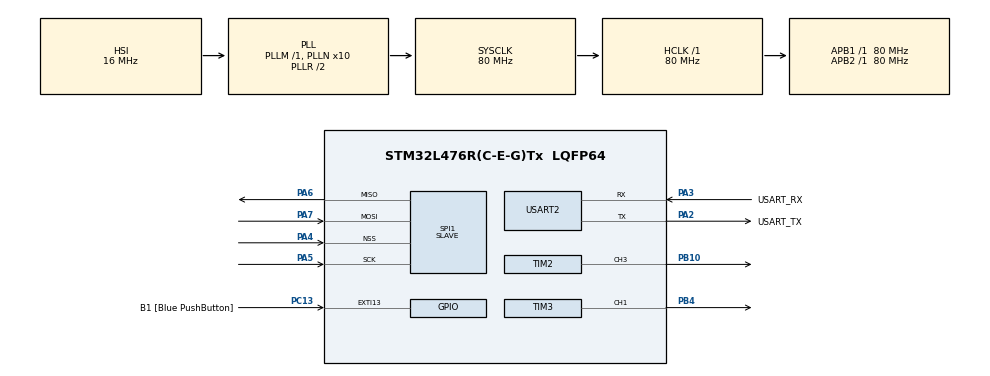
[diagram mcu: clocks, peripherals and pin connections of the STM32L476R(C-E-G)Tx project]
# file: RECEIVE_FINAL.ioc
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Dma.Request0=SPI1_RX
Dma.SPI1_RX.0.Direction=DMA_PERIPH_TO_MEMORY
Dma.SPI1_RX.0.Instance=DMA1_Channel2
Dma.SPI1_RX.0.MemDataAlignment=DMA_MDATAALIGN_BYTE
Dma.SPI1_RX.0.MemInc=DMA_MINC_ENABLE
Dma.SPI1_RX.0.Mode=DMA_NORMAL
Dma.SPI1_RX.0.PeriphDataAlignment=DMA_PDATAALIGN_BYTE
Dma.SPI1_RX.0.PeriphInc=DMA_PINC_DISABLE
Dma.SPI1_RX.0.Priority=DMA_PRIORITY_LOW
FREERTOS.Tasks01=defaultTask,0,128,StartDefaultTask,Default,NULL,Dynamic,NULL,NULL
Mcu.Family=STM32L4
Mcu.Name=STM32L476R(C-E-G)Tx
Mcu.Package=LQFP64
NVIC.DMA1_Channel2_IRQn=true\:5\:0\:false\:false\:true\:true\:false\:true\:true
NVIC.PriorityGroup=NVIC_PRIORITYGROUP_4
PA13\ (JTMS-SWDIO).GPIO_Label=TMS
PA13\ (JTMS-SWDIO).Signal=SYS_JTMS-SWDIO
PA14\ (JTCK-SWCLK).GPIO_Label=TCK
PA14\ (JTCK-SWCLK).Signal=SYS_JTCK-SWCLK
PA2.GPIO_Label=USART_TX
PA2.GPIO_Mode=GPIO_MODE_AF_PP
PA2.GPIO_PuPd=GPIO_NOPULL
PA2.GPIO_Speed=GPIO_SPEED_FREQ_VERY_HIGH
PA2.Mode=Asynchronous
PA2.Signal=USART2_TX
PA3.GPIO_Label=USART_RX
PA3.GPIO_Mode=GPIO_MODE_AF_PP
PA3.GPIO_PuPd=GPIO_NOPULL
PA3.GPIO_Speed=GPIO_SPEED_FREQ_VERY_HIGH
PA3.Mode=Asynchronous
PA3.Signal=USART2_RX
PA4.Mode=NSS_Signal_Hard_Input
PA4.Signal=SPI1_NSS
PA5.Mode=Full_Duplex_Slave
PA5.Signal=SPI1_SCK
PA6.Mode=Full_Duplex_Slave
PA6.Signal=SPI1_MISO
PA7.Mode=Full_Duplex_Slave
PA7.Signal=SPI1_MOSI
PB10.Signal=S_TIM2_CH3
PB3\ (JTDO-TRACESWO).GPIO_Label=SWO
PB3\ (JTDO-TRACESWO).Signal=SYS_JTDO-SWO
PB4\ (NJTRST).Signal=S_TIM3_CH1
PC13.GPIO_Label=B1 [Blue PushButton]
PC13.GPIO_ModeDefaultEXTI=GPIO_MODE_IT_FALLING
PC13.GPIO_PuPd=GPIO_NOPULL
PC13.Signal=GPXTI13
PC14-OSC32_IN\ (PC14).Signal=RCC_OSC32_IN
PC15-OSC32_OUT\ (PC15).Signal=RCC_OSC32_OUT
PH0-OSC_IN\ (PH0).Signal=RCC_OSC_IN
PH1-OSC_OUT\ (PH1).Signal=RCC_OSC_OUT
ProjectManager.HeapSize=0x200
ProjectManager.StackSize=0x400
ProjectManager.TargetToolchain=STM32CubeIDE
RCC.ADCFreq_Value=64000000
RCC.AHBFreq_Value=80000000
RCC.APB1Freq_Value=80000000
RCC.APB1TimFreq_Value=80000000
RCC.APB2Freq_Value=80000000
RCC.APB2TimFreq_Value=80000000
RCC.CortexFreq_Value=80000000
RCC.HCLKFreq_Value=80000000
RCC.HSE_VALUE=8000000
RCC.HSI_VALUE=16000000
RCC.LSE_VALUE=32768
RCC.MSI_VALUE=4000000
RCC.PLLN=10
RCC.PLLSourceVirtual=RCC_PLLSOURCE_HSI
RCC.PREFETCH_ENABLE=1
RCC.SYSCLKFreq_VALUE=80000000
RCC.SYSCLKSource=RCC_SYSCLKSOURCE_PLLCLK
RCC.USBFreq_Value=64000000
RCC.VCOOutputFreq_Value=160000000
SH.S_TIM2_CH3.0=TIM2_CH3,PWM Generation3 CH3
SH.S_TIM3_CH1.0=TIM3_CH1,PWM Generation1 CH1
SPI1.DataSize=SPI_DATASIZE_8BIT
SPI1.Direction=SPI_DIRECTION_2LINES
SPI1.Mode=SPI_MODE_SLAVE
SPI1.VirtualNSS=VM_NSSHARD
SPI1.VirtualType=VM_SLAVE
TIM2.Channel-PWM\ Generation3\ CH3=TIM_CHANNEL_3
TIM2.Period=19999
TIM2.Prescaler=79
TIM3.Channel-PWM\ Generation1\ CH1=TIM_CHANNEL_1
TIM3.Period=19999
TIM3.Prescaler=79
USART2.VirtualMode-Asynchronous=VM_ASYNC
VP_FREERTOS_VS_CMSIS_V1.Mode=CMSIS_V1
board=NUCLEO-L476RG

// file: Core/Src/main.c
/* USER CODE BEGIN Header */
/**
  ******************************************************************************
  * @file           : main.c
  * @brief          : Main program body (peripherals + ISRs + RTOS start)
  ******************************************************************************
  * @attention
  * Copyright (c) 2025 STMicroelectronics.
  * All rights reserved.
  * This software is licensed under terms in the LICENSE file in the root dir.
  ******************************************************************************
  */
/* USER CODE END Header */
#include "main.h"
#include "cmsis_os.h"

/* USER CODE BEGIN Includes */
#include <string.h>
#include <stdio.h>
#include "FreeRTOS.h"
#include "queue.h"
/* USER CODE END Includes */

/* USER CODE BEGIN PTD */
typedef struct { uint8_t bytes[64]; } SpiFrame_t;
/* USER CODE END PTD */

/* USER CODE BEGIN PD */
#define NSS_MON_PORT GPIOB
#define NSS_MON_PIN  GPIO_PIN_0
#define FRAME_LEN    64
/* USER CODE END PD */

SPI_HandleTypeDef hspi1;
DMA_HandleTypeDef hdma_spi1_rx;
DMA_HandleTypeDef hdma_spi1_tx;   /* présent si CubeMX le référence dans MSP */
TIM_HandleTypeDef htim2;          /* TIM2_CH3 -> PB10 (AF1) : direction */
TIM_HandleTypeDef htim3;          /* TIM3_CH1 -> PB4  (AF2) : vitesse */
UART_HandleTypeDef huart2;

/* USER CODE BEGIN PV */
static uint8_t spi_rx_buf[FRAME_LEN];
extern QueueHandle_t spiRxQueue;  /* vient de freertos.c */
/* USER CODE END PV */

void SystemClock_Config(void);
static void MX_GPIO_Init(void);
static void MX_DMA_Init(void);
static void MX_SPI1_Init(void);
static void MX_USART2_UART_Init(void);
static void MX_TIM2_Init(void);
static void MX_TIM3_Init(void);
void MX_FREERTOS_Init(void);

int main(void)
{
  HAL_Init();
  SystemClock_Config();

  MX_GPIO_Init();
  MX_DMA_Init();
  MX_SPI1_Init();
  MX_USART2_UART_Init();
  MX_TIM2_Init();     /* Direction */
  MX_TIM3_Init();     /* Vitesse  */

  MX_FREERTOS_Init();
  osKernelStart();

  while (1) { }
}

/* === Clocks ================================================================ */
void SystemClock_Config(void)
{
  RCC_OscInitTypeDef RCC_OscInitStruct = {0};
  RCC_ClkInitTypeDef RCC_ClkInitStruct = {0};

  if (HAL_PWREx_ControlVoltageScaling(PWR_REGULATOR_VOLTAGE_SCALE1) != HAL_OK) {
    Error_Handler();
  }

  RCC_OscInitStruct.OscillatorType      = RCC_OSCILLATORTYPE_HSI;
  RCC_OscInitStruct.HSIState            = RCC_HSI_ON;
  RCC_OscInitStruct.HSICalibrationValue = RCC_HSICALIBRATION_DEFAULT;
  RCC_OscInitStruct.PLL.PLLState        = RCC_PLL_ON;
  RCC_OscInitStruct.PLL.PLLSource       = RCC_PLLSOURCE_HSI;
  RCC_OscInitStruct.PLL.PLLM            = 1;
  RCC_OscInitStruct.PLL.PLLN            = 10;
  RCC_OscInitStruct.PLL.PLLP            = RCC_PLLP_DIV7;
  RCC_OscInitStruct.PLL.PLLQ            = RCC_PLLQ_DIV2;
  RCC_OscInitStruct.PLL.PLLR            = RCC_PLLR_DIV2;
  if (HAL_RCC_OscConfig(&RCC_OscInitStruct) != HAL_OK) Error_Handler();

  RCC_ClkInitStruct.ClockType      = RCC_CLOCKTYPE_HCLK|RCC_CLOCKTYPE_SYSCLK
                                   | RCC_CLOCKTYPE_PCLK1|RCC_CLOCKTYPE_PCLK2;
  RCC_ClkInitStruct.SYSCLKSource   = RCC_SYSCLKSOURCE_PLLCLK;
  RCC_ClkInitStruct.AHBCLKDivider  = RCC_SYSCLK_DIV1;
  RCC_ClkInitStruct.APB1CLKDivider = RCC_HCLK_DIV1;
  RCC_ClkInitStruct.APB2CLKDivider = RCC_HCLK_DIV1;
  if (HAL_RCC_ClockConfig(&RCC_ClkInitStruct, FLASH_LATENCY_4) != HAL_OK) Error_Handler();
}

/* === SPI1 (slave) ========================================================== */
static void MX_SPI1_Init(void)
{
  hspi1.Instance               = SPI1;
  hspi1.Init.Mode              = SPI_MODE_SLAVE;
  hspi1.Init.Direction         = SPI_DIRECTION_2LINES;
  hspi1.Init.DataSize          = SPI_DATASIZE_8BIT;
  hspi1.Init.CLKPolarity       = SPI_POLARITY_LOW;
  hspi1.Init.CLKPhase          = SPI_PHASE_1EDGE;
  hspi1.Init.NSS               = SPI_NSS_HARD_INPUT;
  hspi1.Init.FirstBit          = SPI_FIRSTBIT_MSB;
  hspi1.Init.TIMode            = SPI_TIMODE_DISABLE;
  hspi1.Init.CRCCalculation    = SPI_CRCCALCULATION_DISABLE;
  hspi1.Init.CRCPolynomial     = 7;
  hspi1.Init.CRCLength         = SPI_CRC_LENGTH_DATASIZE;
  hspi1.Init.NSSPMode          = SPI_NSS_PULSE_DISABLE;
  if (HAL_SPI_Init(&hspi1) != HAL_OK) Error_Handler();
}

/* === UART2 ================================================================ */
static void MX_USART2_UART_Init(void)
{
  huart2.Instance                    = USART2;
  huart2.Init.BaudRate               = 115200;
  huart2.Init.WordLength             = UART_WORDLENGTH_8B;
  huart2.Init.StopBits               = UART_STOPBITS_1;
  huart2.Init.Parity                 = UART_PARITY_NONE;
  huart2.Init.Mode                   = UART_MODE_TX_RX;
  huart2.Init.HwFlowCtl              = UART_HWCONTROL_NONE;
  huart2.Init.OverSampling           = UART_OVERSAMPLING_16;
  huart2.Init.OneBitSampling         = UART_ONE_BIT_SAMPLE_DISABLE;
  huart2.AdvancedInit.AdvFeatureInit = UART_ADVFEATURE_NO_INIT;
  if (HAL_UART_Init(&huart2) != HAL_OK) Error_Handler();
}

/* === DMA (SPI1 RX sur DMA1_Ch2) =========================================== */
static void MX_DMA_Init(void)
{
  __HAL_RCC_DMA1_CLK_ENABLE();
  HAL_NVIC_SetPriority(DMA1_Channel2_IRQn, 5, 0);
  HAL_NVIC_EnableIRQ(DMA1_Channel2_IRQn);
}

/* === GPIO (PB0 EXTI pour NSS monitor) ===================================== */
static void MX_GPIO_Init(void)
{
  GPIO_InitTypeDef GPIO_InitStruct = {0};

  __HAL_RCC_GPIOC_CLK_ENABLE();
  __HAL_RCC_GPIOH_CLK_ENABLE();
  __HAL_RCC_GPIOA_CLK_ENABLE();
  __HAL_RCC_GPIOB_CLK_ENABLE();
  __HAL_RCC_SYSCFG_CLK_ENABLE();

  /* Bouton B1 (généré par Cube) */
  GPIO_InitStruct.Pin  = B1_Pin;
  GPIO_InitStruct.Mode = GPIO_MODE_IT_FALLING;
  GPIO_InitStruct.Pull = GPIO_NOPULL;
  HAL_GPIO_Init(B1_GPIO_Port, &GPIO_InitStruct);

  /* PB0 EXTI falling (copie NSS/CS de l’ESP32) */
  GPIO_InitStruct.Pin  = GPIO_PIN_0;
  GPIO_InitStruct.Mode = GPIO_MODE_IT_FALLING;
  GPIO_InitStruct.Pull = GPIO_PULLUP;
  HAL_GPIO_Init(GPIOB, &GPIO_InitStruct);

  HAL_NVIC_SetPriority(EXTI0_IRQn, 5, 0);
  HAL_NVIC_EnableIRQ(EXTI0_IRQn);
}

/* === TIM2_CH3 (PB10) & TIM3_CH1 (PB4) en 50 Hz ============================ */
static void MX_TIM2_Init(void)
{
  __HAL_RCC_TIM2_CLK_ENABLE();

  htim2.Instance = TIM2;
  htim2.Init.Prescaler         = 80 - 1;     /* 1 MHz */
  htim2.Init.CounterMode       = TIM_COUNTERMODE_UP;
  htim2.Init.Period            = 20000 - 1;  /* 20 ms (50 Hz) */
  htim2.Init.ClockDivision     = TIM_CLOCKDIVISION_DIV1;
  htim2.Init.AutoReloadPreload = TIM_AUTORELOAD_PRELOAD_DISABLE;
  if (HAL_TIM_PWM_Init(&htim2) != HAL_OK) Error_Handler();

  TIM_OC_InitTypeDef s = {0};
  s.OCMode     = TIM_OCMODE_PWM1;
  s.Pulse      = 1400;                       /* neutre */
  s.OCPolarity = TIM_OCPOLARITY_HIGH;
  s.OCFastMode = TIM_OCFAST_DISABLE;
  if (HAL_TIM_PWM_ConfigChannel(&htim2, &s, TIM_CHANNEL_3) != HAL_OK) Error_Handler();

  HAL_TIM_MspPostInit(&htim2);               /* configure PB10 AF1 */
}

static void MX_TIM3_Init(void)
{
  __HAL_RCC_TIM3_CLK_ENABLE();

  htim3.Instance = TIM3;
  htim3.Init.Prescaler         = 80 - 1;     /* 1 MHz */
  htim3.Init.CounterMode       = TIM_COUNTERMODE_UP;
  htim3.Init.Period            = 20000 - 1;  /* 20 ms (50 Hz) */
  htim3.Init.ClockDivision     = TIM_CLOCKDIVISION_DIV1;
  htim3.Init.AutoReloadPreload = TIM_AUTORELOAD_PRELOAD_DISABLE;
  if (HAL_TIM_PWM_Init(&htim3) != HAL_OK) Error_Handler();

  TIM_OC_InitTypeDef s = {0};
  s.OCMode     = TIM_OCMODE_PWM1;
  s.Pulse      = 1400;                       /* neutre */
  s.OCPolarity = TIM_OCPOLARITY_HIGH;
  s.OCFastMode = TIM_OCFAST_DISABLE;
  if (HAL_TIM_PWM_ConfigChannel(&htim3, &s, TIM_CHANNEL_1) != HAL_OK) Error_Handler();

  HAL_TIM_MspPostInit(&htim3);               /* configure PB4 AF2 */
}

/* === ISRs / Callbacks ====================================================== */
void HAL_GPIO_EXTI_Callback(uint16_t GPIO_Pin)
{
  if (GPIO_Pin == NSS_MON_PIN) {
    if (HAL_SPI_GetState(&hspi1) == HAL_SPI_STATE_READY) {
      (void)HAL_SPI_Receive_DMA(&hspi1, spi_rx_buf, FRAME_LEN);
    }
  }
}

void HAL_SPI_RxCpltCallback(SPI_HandleTypeDef *hspi)
{
  if (hspi->Instance == SPI1) {
    BaseType_t xHigherPriorityTaskWoken = pdFALSE;
    SpiFrame_t frame;
    memcpy(frame.bytes, spi_rx_buf, FRAME_LEN);
    if (spiRxQueue) {
      xQueueSendFromISR(spiRxQueue, &frame, &xHigherPriorityTaskWoken);
    }
    portYIELD_FROM_ISR(xHigherPriorityTaskWoken);
  }
}

void HAL_SPI_ErrorCallback(SPI_HandleTypeDef *hspi)
{
  if (hspi->Instance == SPI1) {
    (void)HAL_SPI_Abort(hspi);
  }
}

void Error_Handler(void)
{
  __disable_irq();
  while (1) { }
}

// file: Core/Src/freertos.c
/**
  ******************************************************************************
  * @file    freertos.c
  * @brief   RTOS objects: queues, tasks, MX_FREERTOS_Init()
  ******************************************************************************
  */

#include "cmsis_os.h"
#include "main.h"

/* FreeRTOS */
#include "FreeRTOS.h"
#include "queue.h"
#include "task.h"

/* C std */
#include <string.h>
#include <stdio.h>
#include <stdint.h>

/* Extern HAL handles (from main.c) */
extern UART_HandleTypeDef huart2;
extern TIM_HandleTypeDef  htim2;   /* TIM2_CH3 -> PB10 (AF1) */
extern TIM_HandleTypeDef  htim3;   /* TIM3_CH1 -> PB4  (AF2) */

/* Partagé avec l'ISR SPI */
QueueHandle_t spiRxQueue = NULL;

/* Etats (optionnel) */
volatile float LX_value;
volatile float RT_value;
volatile float LT_value;

/* Trame SPI brute */
#define FRAME_LEN  64
typedef struct { uint8_t bytes[FRAME_LEN]; } SpiFrame_t;

/* Protos */
static void StartDefaultTask(void const * argument);
void StartDirTask(void const * argument);
void StartSpdTask(void const * argument);

/* Format décodé (offset 3) */
typedef struct {
  uint32_t buttons;
  float    lx;
  float    ly;
  float    rx;
  float    ry;
  float    lt;
  float    rt;
} GamepadFrame_t;

static inline uint32_t read_u32_le(const uint8_t *p) { uint32_t v; memcpy(&v,p,4); return v; }
static inline float    read_f32_le(const uint8_t *p) { float    f; memcpy(&f,p,4); return f; }

static void decode_gamepad_frame(const uint8_t *data, GamepadFrame_t *out)
{
  size_t off = 3;  /* on saute 3 octets */
  out->buttons = read_u32_le(&data[off]); off += 4;
  out->lx      = read_f32_le(&data[off]); off += 4;
  out->ly      = read_f32_le(&data[off]); off += 4;
  out->rx      = read_f32_le(&data[off]); off += 4;
  out->ry      = read_f32_le(&data[off]); off += 4;
  out->lt      = read_f32_le(&data[off]); off += 4;
  out->rt      = read_f32_le(&data[off]); off += 4;
}

/* Messages des queues */
typedef struct { float lx; } DirectionMsg;
typedef struct { float lt; float rt; } VitesseMsg;

QueueHandle_t qDirection = NULL;
QueueHandle_t qVitesse   = NULL;

/* Bornes et gains */
static const uint16_t DIR_MIN    = 1200;
static const uint16_t DIR_CENTER = 1400;
static const uint16_t DIR_MAX    = 1600;
static const int16_t  DIR_SCALE  = 200;   /* duty_dir = 1400 - 200*lx */

static const uint16_t SPD_CENTER = 1400;  /* test_v1 neutre */
static const uint16_t SPD_MIN    = 1300;
static const uint16_t SPD_MAX    = 1500;
static const int16_t  SPD_SCALE  = 50;    /* duty_spd = 1400 + 50*(rt - lt) */

static inline int clamp_i(int v, int lo, int hi) {
  if (v < lo) return lo; if (v > hi) return hi; return v;
}

static void fmt_f2(char *dst, size_t sz, float v)
{
  int neg = (v < 0.0f);
  float a = neg ? -v : v;
  int32_t ip = (int32_t)a;
  int32_t frac = (int32_t)((a - (float)ip)*100.0f + 0.5f);
  if (frac >= 100) { frac -= 100; ip += 1; }
  snprintf(dst, sz, neg ? "-%ld.%02ld" : "%ld.%02ld", (long)ip, (long)frac);
}

/* Log de config PWM et AF des pins */
static void LogPwmSetupOnce(void)
{
  uint32_t t2_psc = htim2.Init.Prescaler, t2_arr = htim2.Init.Period;
  uint32_t t3_psc = htim3.Init.Prescaler, t3_arr = htim3.Init.Period;
  uint32_t af_pb10 = (GPIOB->AFR[1] >> ((10U-8U)*4U)) & 0xF;  /* PB10 -> AFRH idx 2 */
  uint32_t af_pb4  = (GPIOB->AFR[0] >> (4U*4U)) & 0xF;        /* PB4  -> AFRL idx 4  */

  char buf[196];
  int n = snprintf(buf, sizeof buf,
      "[CFG] TIM2:PSC=%lu ARR=%lu  TIM3:PSC=%lu ARR=%lu\r\n"
      "[CFG] PB10.AF=%lu (exp 1)   PB4.AF=%lu (exp 2)\r\n"
      "[CFG] DIR[%u,%u,%u]  SPD[%u,%u,%u]\r\n",
      (unsigned long)t2_psc, (unsigned long)t2_arr,
      (unsigned long)t3_psc, (unsigned long)t3_arr,
      (unsigned long)af_pb10, (unsigned long)af_pb4,
      DIR_MIN, DIR_CENTER, DIR_MAX, SPD_MIN, SPD_CENTER, SPD_MAX);
  HAL_UART_Transmit(&huart2, (uint8_t*)buf, (uint16_t)n, 100);
}

/* Init FreeRTOS */
void MX_FREERTOS_Init(void)
{
  /* Banniere pour être sûr de l’image flashée */
  {
    char b[96];
    int n = snprintf(b, sizeof b, "[BOOT] FW=%s %s\r\n", __DATE__, __TIME__);
    HAL_UART_Transmit(&huart2, (uint8_t*)b, (uint16_t)n, 50);
  }

  spiRxQueue = xQueueCreate(8, sizeof(SpiFrame_t));
  if (!spiRxQueue) { taskDISABLE_INTERRUPTS(); for(;;){} }

  qDirection = xQueueCreate(1, sizeof(DirectionMsg));
  qVitesse   = xQueueCreate(1, sizeof(VitesseMsg));

  {
    char buf[96];
    int n = snprintf(buf, sizeof buf, "[BOOT] qDir=%p qSpd=%p free=%lu min=%lu\r\n",
                     (void*)qDirection, (void*)qVitesse,
                     (unsigned long)xPortGetFreeHeapSize(),
                     (unsigned long)xPortGetMinimumEverFreeHeapSize());
    HAL_UART_Transmit(&huart2, (uint8_t*)buf, (uint16_t)n, 50);
  }

  osThreadDef(defaultTask, StartDefaultTask, osPriorityNormal, 0, 256);
  osThreadId defH = osThreadCreate(osThread(defaultTask), NULL);

  osThreadDef(dirTask, StartDirTask, osPriorityAboveNormal, 0, 256);
  osThreadId dirH = osThreadCreate(osThread(dirTask), NULL);

  osThreadDef(spdTask, StartSpdTask, osPriorityAboveNormal, 0, 256);
  osThreadId spdH = osThreadCreate(osThread(spdTask), NULL);

  {
    char buf[96];
    int n = snprintf(buf, sizeof buf, "[BOOT] default=%p dir=%p spd=%p\r\n",
                     defH, dirH, spdH);
    HAL_UART_Transmit(&huart2, (uint8_t*)buf, (uint16_t)n, 50);
  }

  LogPwmSetupOnce();
}

/* ==== TASKS ================================================================ */
static void StartDefaultTask(void const * argument)
{
  SpiFrame_t frame;
  GamepadFrame_t g;

  for(;;) {
    if (xQueueReceive(spiRxQueue, &frame, portMAX_DELAY) == pdTRUE) {
      decode_gamepad_frame(frame.bytes, &g);

      LT_value = g.lt;
      RT_value = g.rt;
      LX_value = g.lx;

      DirectionMsg dmsg = { .lx = LX_value };
      VitesseMsg   vmsg = { .lt = LT_value, .rt = RT_value };
      (void)xQueueOverwrite(qDirection, &dmsg);
      (void)xQueueOverwrite(qVitesse,   &vmsg);

      char lx[12], lt[12], rt[12], line[64];
      fmt_f2(lx, sizeof lx, LX_value);
      fmt_f2(lt, sizeof lt, LT_value);
      fmt_f2(rt, sizeof rt, RT_value);
      int n = snprintf(line, sizeof line, "LX=%s  LT=%s  RT=%s\r\n", lx, lt, rt);
      HAL_UART_Transmit(&huart2, (uint8_t*)line, (uint16_t)n, 50);
    }
  }
}

/* Direction : TIM2_CH3 / PB10 */
void StartDirTask(void const * argument)
{
  HAL_UART_Transmit(&huart2, (uint8_t*)"[DIR] entering\r\n", 16, 10);

  if (HAL_TIM_PWM_Start(&htim2, TIM_CHANNEL_3) != HAL_OK) {
    HAL_UART_Transmit(&huart2, (uint8_t*)"[DIR] ERR start PWM\r\n", 22, 10);
    vTaskSuspend(NULL);
  }
  __HAL_TIM_SET_COMPARE(&htim2, TIM_CHANNEL_3, DIR_CENTER);
  HAL_UART_Transmit(&huart2, (uint8_t*)"[DIR] up, CCR=1400\r\n", 19, 10);

  DirectionMsg msg;
  int lastDuty = -1;

  for (;;) {
    if (xQueueReceive(qDirection, &msg, portMAX_DELAY) == pdTRUE) {
      /* sens inversé validé en test: gauche/droite corrigés */
      int duty = (int)(DIR_CENTER - (int)(DIR_SCALE * msg.lx));
      int clamped = clamp_i(duty, DIR_MIN, DIR_MAX);
      if (clamped != duty) {
        char w[40]; int n = snprintf(w, sizeof w, "[DIR] clamp %d->%d\r\n", duty, clamped);
        HAL_UART_Transmit(&huart2, (uint8_t*)w, (uint16_t)n, 10);
        duty = clamped;
      }
      if (duty != lastDuty) {
        __HAL_TIM_SET_COMPARE(&htim2, TIM_CHANNEL_3, (uint16_t)duty);
        char l[32]; int n = snprintf(l, sizeof l, "[DIR] CCR=%d\r\n", duty);
        HAL_UART_Transmit(&huart2, (uint8_t*)l, (uint16_t)n, 10);
        lastDuty = duty;
      }
    }
  }
}

/* Vitesse : TIM3_CH1 / PB4 */
void StartSpdTask(void const * argument)
{
  HAL_UART_Transmit(&huart2, (uint8_t*)"[SPD] entering\r\n", 16, 10);

  if (HAL_TIM_PWM_Start(&htim3, TIM_CHANNEL_1) != HAL_OK) {
    HAL_UART_Transmit(&huart2, (uint8_t*)"[SPD] ERR start PWM\r\n", 22, 10);
    vTaskSuspend(NULL);
  }
  __HAL_TIM_SET_COMPARE(&htim3, TIM_CHANNEL_1, SPD_CENTER);
  HAL_UART_Transmit(&huart2, (uint8_t*)"[SPD] up, CCR=1400\r\n", 19, 10);

  VitesseMsg msg;
  int lastDuty = -1;

  for (;;) {
    if (xQueueReceive(qVitesse, &msg, portMAX_DELAY) == pdTRUE) {
      float net = (msg.rt - msg.lt);                /* test_v1 */
      int duty  = (int)(SPD_CENTER + (int)(SPD_SCALE * net));
      int clamped = clamp_i(duty, SPD_MIN, SPD_MAX);
      if (clamped != duty) {
        char w[40]; int n = snprintf(w, sizeof w, "[SPD] clamp %d->%d\r\n", duty, clamped);
        HAL_UART_Transmit(&huart2, (uint8_t*)w, (uint16_t)n, 10);
        duty = clamped;
      }
      if (duty != lastDuty) {
        __HAL_TIM_SET_COMPARE(&htim3, TIM_CHANNEL_1, (uint16_t)duty);
        char l[32]; int n = snprintf(l, sizeof l, "[SPD] CCR=%d\r\n", duty);
        HAL_UART_Transmit(&huart2, (uint8_t*)l, (uint16_t)n, 10);
        lastDuty = duty;
      }
    }
  }
}

/* ==== Static allocation callbacks (si STATIC=1) ============================ */
#include "FreeRTOS.h"
static StaticTask_t xIdleTaskTCBBuffer;
static StackType_t  xIdleStack[configMINIMAL_STACK_SIZE];
void vApplicationGetIdleTaskMemory( StaticTask_t **ppxIdleTaskTCBBuffer,
                                    StackType_t  **ppxIdleTaskStackBuffer,
                                    uint32_t     *pulIdleTaskStackSize )
{
  *ppxIdleTaskTCBBuffer = &xIdleTaskTCBBuffer;
  *ppxIdleTaskStackBuffer = xIdleStack;
  *pulIdleTaskStackSize = configMINIMAL_STACK_SIZE;
}

#if ( configUSE_TIMERS == 1 )
static StaticTask_t xTimerTaskTCBBuffer;
static StackType_t  xTimerStack[ configTIMER_TASK_STACK_DEPTH ];
void vApplicationGetTimerTaskMemory( StaticTask_t **ppxTimerTaskTCBBuffer,
                                     StackType_t  **ppxTimerTaskStackBuffer,
                                     uint32_t     *pulTimerTaskStackSize )
{
  *ppxTimerTaskTCBBuffer = &xTimerTaskTCBBuffer;
  *ppxTimerTaskStackBuffer = xTimerStack;
  *pulTimerTaskStackSize = configTIMER_TASK_STACK_DEPTH;
}
#endif

/* ==== Hooks diag =========================================================== */
void vApplicationMallocFailedHook(void)
{
  const char* msg = "[ERR] malloc failed\r\n";
  HAL_UART_Transmit(&huart2,(uint8_t*)msg,(uint16_t)strlen(msg),50);
  taskDISABLE_INTERRUPTS(); for(;;){}
}

void vApplicationStackOverflowHook(TaskHandle_t xTask, char *pcTaskName)
{
  char buf[64];
  int n = snprintf(buf,sizeof buf,"[ERR] stack overflow: %s\r\n", pcTaskName);
  HAL_UART_Transmit(&huart2,(uint8_t*)buf,(uint16_t)n,50);
  taskDISABLE_INTERRUPTS(); for(;;){}
}
